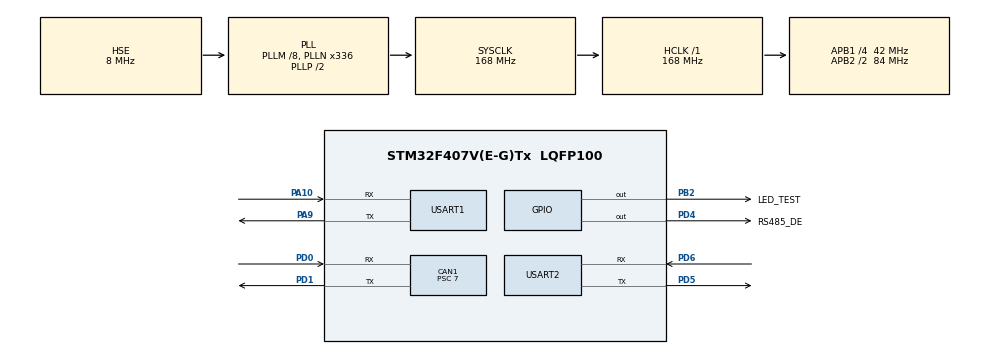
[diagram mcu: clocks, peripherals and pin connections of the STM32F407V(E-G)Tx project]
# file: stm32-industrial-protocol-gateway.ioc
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CAN1.ABOM=ENABLE
CAN1.BS1=CAN_BS1_6TQ
CAN1.BS2=CAN_BS2_5TQ
CAN1.CalculateBaudRate=499999
CAN1.CalculateTimeBit=2000
CAN1.CalculateTimeQuantum=166.66666666666669
CAN1.Mode=CAN_MODE_NORMAL
CAN1.NART=ENABLE
CAN1.Prescaler=7
CAN1.SJW=CAN_SJW_2TQ
Dma.Request0=USART2_RX
Dma.Request1=USART2_TX
Dma.USART2_RX.0.Direction=DMA_PERIPH_TO_MEMORY
Dma.USART2_RX.0.FIFOMode=DMA_FIFOMODE_DISABLE
Dma.USART2_RX.0.Instance=DMA1_Stream5
Dma.USART2_RX.0.MemDataAlignment=DMA_MDATAALIGN_BYTE
Dma.USART2_RX.0.MemInc=DMA_MINC_ENABLE
Dma.USART2_RX.0.Mode=DMA_CIRCULAR
Dma.USART2_RX.0.PeriphDataAlignment=DMA_PDATAALIGN_BYTE
Dma.USART2_RX.0.PeriphInc=DMA_PINC_DISABLE
Dma.USART2_RX.0.Priority=DMA_PRIORITY_MEDIUM
Dma.USART2_TX.1.Direction=DMA_MEMORY_TO_PERIPH
Dma.USART2_TX.1.FIFOMode=DMA_FIFOMODE_DISABLE
Dma.USART2_TX.1.Instance=DMA1_Stream6
Dma.USART2_TX.1.MemDataAlignment=DMA_MDATAALIGN_BYTE
Dma.USART2_TX.1.MemInc=DMA_MINC_ENABLE
Dma.USART2_TX.1.Mode=DMA_NORMAL
Dma.USART2_TX.1.PeriphDataAlignment=DMA_PDATAALIGN_BYTE
Dma.USART2_TX.1.PeriphInc=DMA_PINC_DISABLE
Dma.USART2_TX.1.Priority=DMA_PRIORITY_MEDIUM
Mcu.Family=STM32F4
Mcu.Name=STM32F407V(E-G)Tx
Mcu.Package=LQFP100
NVIC.CAN1_RX0_IRQn=true\:9\:0\:true\:false\:true\:true\:true\:true
NVIC.CAN1_RX1_IRQn=true\:9\:0\:true\:false\:true\:true\:true\:true
NVIC.CAN1_TX_IRQn=true\:9\:0\:true\:false\:true\:true\:true\:true
NVIC.DMA1_Stream5_IRQn=true\:10\:0\:true\:false\:true\:false\:true\:true
NVIC.DMA1_Stream6_IRQn=true\:10\:0\:true\:false\:true\:false\:true\:true
NVIC.PriorityGroup=NVIC_PRIORITYGROUP_4
NVIC.TIM6_DAC_IRQn=true\:15\:0\:false\:false\:true\:false\:true\:true
NVIC.TimeBase=TIM6_DAC_IRQn
NVIC.TimeBaseIP=TIM6
NVIC.USART1_IRQn=true\:10\:0\:true\:false\:true\:true\:true\:true
NVIC.USART2_IRQn=true\:10\:0\:true\:false\:true\:true\:true\:true
PA10.Mode=Asynchronous
PA10.Signal=USART1_RX
PA13.Mode=Serial_Wire
PA13.Signal=SYS_JTMS-SWDIO
PA14.Mode=Serial_Wire
PA14.Signal=SYS_JTCK-SWCLK
PA9.Mode=Asynchronous
PA9.Signal=USART1_TX
PB2.GPIO_Label=LED_TEST
PB2.GPIO_ModeDefaultOutputPP=GPIO_MODE_OUTPUT_PP
PB2.PinState=GPIO_PIN_SET
PB2.Signal=GPIO_Output
PD0.Mode=CAN_Activate
PD0.Signal=CAN1_RX
PD1.Mode=CAN_Activate
PD1.Signal=CAN1_TX
PD4.GPIO_Label=RS485_DE
PD4.Signal=GPIO_Output
PD5.Mode=Asynchronous
PD5.Signal=USART2_TX
PD6.Mode=Asynchronous
PD6.Signal=USART2_RX
PH0-OSC_IN.Mode=HSE-External-Oscillator
PH0-OSC_IN.Signal=RCC_OSC_IN
PH1-OSC_OUT.Mode=HSE-External-Oscillator
PH1-OSC_OUT.Signal=RCC_OSC_OUT
ProjectManager.HeapSize=0x200
ProjectManager.StackSize=0x400
ProjectManager.TargetToolchain=CMake
RCC.48MHZClocksFreq_Value=84000000
RCC.AHBFreq_Value=168000000
RCC.APB1CLKDivider=RCC_HCLK_DIV4
RCC.APB1Freq_Value=42000000
RCC.APB1TimFreq_Value=84000000
RCC.APB2CLKDivider=RCC_HCLK_DIV2
RCC.APB2Freq_Value=84000000
RCC.APB2TimFreq_Value=168000000
RCC.CortexFreq_Value=168000000
RCC.HCLKFreq_Value=168000000
RCC.HSE_VALUE=8000000
RCC.HSI_VALUE=16000000
RCC.LSE_VALUE=32768
RCC.PLLM=8
RCC.PLLN=336
RCC.PLLSourceVirtual=RCC_PLLSOURCE_HSE
RCC.SYSCLKFreq_VALUE=168000000
RCC.SYSCLKSource=RCC_SYSCLKSOURCE_PLLCLK
RCC.VCOOutputFreq_Value=336000000
USART1.VirtualMode=VM_ASYNC
USART2.VirtualMode=VM_ASYNC
VP_SYS_VS_tim6.Mode=TIM6
board=custom

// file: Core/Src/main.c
/* USER CODE BEGIN Header */
/**
  ******************************************************************************
  * @file           : main.c
  * @brief          : Main program body
  ******************************************************************************
  * @attention
  *
  * Copyright (c) 2026 STMicroelectronics.
  * All rights reserved.
  *
  * This software is licensed under terms that can be found in the LICENSE file
  * in the root directory of this software component.
  * If no LICENSE file comes with this software, it is provided AS-IS.
  *
  ******************************************************************************
  */
/* USER CODE END Header */
#include "main.h"
#include "can.h"
#include "dma.h"
#include "usart.h"
#include "gpio.h"

/* USER CODE BEGIN Includes */
#include "app.h"
/* USER CODE END Includes */

/* USER CODE BEGIN PV */

volatile uint8_t malloc_failed_flag = 0;

TaskHandle_t volatile stack_overflow_task = NULL;
const char * volatile stack_overflow_task_name = NULL;

/* USER CODE END PV */

void SystemClock_Config(void);

int main(void)
{

  /* MCU Configuration--------------------------------------------------------*/

  /* Reset of all peripherals, Initializes the Flash interface and the Systick. */
  HAL_Init();

  /* Configure the system clock */
  SystemClock_Config();

  /* Initialize all configured peripherals */
  MX_GPIO_Init();
  MX_DMA_Init();
  MX_CAN1_Init();
  MX_USART1_UART_Init();
  MX_USART2_UART_Init();

  /* Infinite loop */
  /* USER CODE BEGIN WHILE */
  app();
  while (1)
  {
    /* USER CODE END WHILE */

  }
}

void SystemClock_Config(void)
{
  RCC_OscInitTypeDef RCC_OscInitStruct = {0};
  RCC_ClkInitTypeDef RCC_ClkInitStruct = {0};

  /** Configure the main internal regulator output voltage
  */
  __HAL_RCC_PWR_CLK_ENABLE();
  __HAL_PWR_VOLTAGESCALING_CONFIG(PWR_REGULATOR_VOLTAGE_SCALE1);

  /** Initializes the RCC Oscillators according to the specified parameters
  * in the RCC_OscInitTypeDef structure.
  */
  RCC_OscInitStruct.OscillatorType = RCC_OSCILLATORTYPE_HSE;
  RCC_OscInitStruct.HSEState = RCC_HSE_ON;
  RCC_OscInitStruct.PLL.PLLState = RCC_PLL_ON;
  RCC_OscInitStruct.PLL.PLLSource = RCC_PLLSOURCE_HSE;
  RCC_OscInitStruct.PLL.PLLM = 8;
  RCC_OscInitStruct.PLL.PLLN = 336;
  RCC_OscInitStruct.PLL.PLLP = RCC_PLLP_DIV2;
  RCC_OscInitStruct.PLL.PLLQ = 4;
  if (HAL_RCC_OscConfig(&RCC_OscInitStruct) != HAL_OK)
  {
    Error_Handler();
  }

  /** Initializes the CPU, AHB and APB buses clocks
  */
  RCC_ClkInitStruct.ClockType = RCC_CLOCKTYPE_HCLK|RCC_CLOCKTYPE_SYSCLK
                              |RCC_CLOCKTYPE_PCLK1|RCC_CLOCKTYPE_PCLK2;
  RCC_ClkInitStruct.SYSCLKSource = RCC_SYSCLKSOURCE_PLLCLK;
  RCC_ClkInitStruct.AHBCLKDivider = RCC_SYSCLK_DIV1;
  RCC_ClkInitStruct.APB1CLKDivider = RCC_HCLK_DIV4;
  RCC_ClkInitStruct.APB2CLKDivider = RCC_HCLK_DIV2;

  if (HAL_RCC_ClockConfig(&RCC_ClkInitStruct, FLASH_LATENCY_5) != HAL_OK)
  {
    Error_Handler();
  }
}

/* USER CODE BEGIN 4 */

void vApplicationMallocFailedHook(void) {
  malloc_failed_flag = 1;
  taskDISABLE_INTERRUPTS();
  while (1) {
    __NOP();
  }
}

void vApplicationStackOverflowHook(TaskHandle_t xTask, char *pcTaskName) {
  stack_overflow_task = xTask;
  stack_overflow_task_name = pcTaskName;
  taskDISABLE_INTERRUPTS();
  while (1) {
    __NOP();
  }
}

/* USER CODE END 4 */

void HAL_TIM_PeriodElapsedCallback(TIM_HandleTypeDef *htim)
{
  if (htim->Instance == TIM6)
  {
    HAL_IncTick();
  }
}

void Error_Handler(void)
{
  __disable_irq();
  while (1)
  {
  }
}
